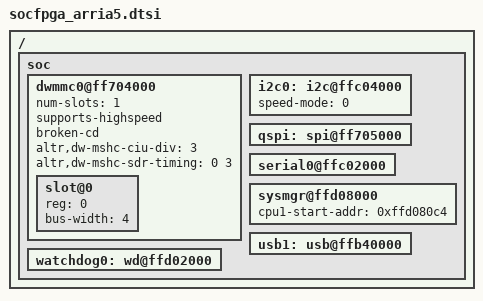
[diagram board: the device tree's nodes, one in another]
/*
 * Copyright Altera Corporation (C) 2013-2014. All rights reserved.
 *
 * This program is free software; you can redistribute it and/or modify
 * it under the terms and conditions of the GNU General Public License,
 * version 2, as published by the Free Software Foundation.
 *
 * This program is distributed in the hope it will be useful, but WITHOUT
 * ANY WARRANTY; without even the implied warranty of MERCHANTABILITY or
 * FITNESS FOR A PARTICULAR PURPOSE.  See the GNU General Public License for
 * more details.
 *
 * You should have received a copy of the GNU General Public License along with
 * this program.  If not, see <http://www.gnu.org/licenses/>.
 */

/dts-v1/;
/include/ "socfpga.dtsi"

/ {
	soc {
		dwmmc0@ff704000 {
			num-slots = <1>;
			supports-highspeed;
			broken-cd;
			altr,dw-mshc-ciu-div = <3>;
			altr,dw-mshc-sdr-timing = <0 3>;

			slot@0 {
				reg = <0>;
				bus-width = <4>;
			};
		};

		i2c0: i2c@ffc04000 {
			speed-mode = <0>;
			status = "okay";
		};

		qspi: spi@ff705000 {
			status = "okay";
		};

		serial0@ffc02000 {
			status = "okay";
		};

		sysmgr@ffd08000 {
			cpu1-start-addr = <0xffd080c4>;
		};

		usb1: usb@ffb40000 {
			status = "okay";
		};

		watchdog0: wd@ffd02000 {
			status = "okay";
		};

	};
};
